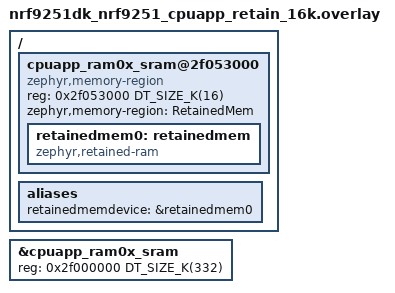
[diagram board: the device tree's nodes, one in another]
#include "nrf9251dk_nrf9251_cpuapp.overlay"

/ {
	cpuapp_ram0x_sram@2f053000 {
		compatible = "zephyr,memory-region", "mmio-sram";
		reg = <0x2f053000 DT_SIZE_K(16)>;
		zephyr,memory-region = "RetainedMem";
		status = "okay";

		retainedmem0: retainedmem {
			compatible = "zephyr,retained-ram";
			status = "okay";
		};
	};

	aliases {
		retainedmemdevice = &retainedmem0;
	};
};

&cpuapp_ram0x_sram {
	/* Shrink SRAM size to avoid overlap with retained memory region:
	 * 348 - 16 = 332 (0x53000)
	 */
	reg = <0x2f000000 DT_SIZE_K(332)>;
	ranges = <0x0 0x2f000000 DT_SIZE_K(332)>;
};
